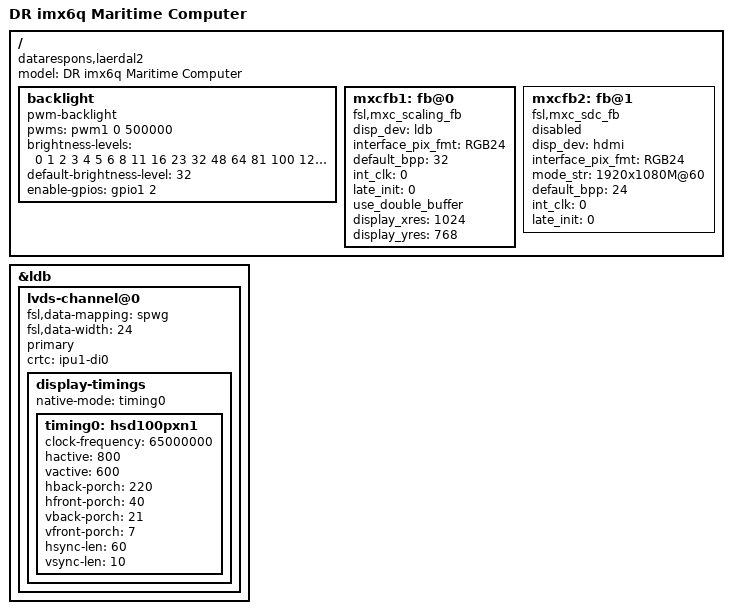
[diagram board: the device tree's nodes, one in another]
/*
 * Copyright 2015 DATA RESPONS AS
 * Copyright 2012 Freescale Semiconductor, Inc.
 * Copyright 2011 Linaro Ltd.
 *
 * The code contained herein is licensed under the GNU General Public
 * License. You may obtain a copy of the GNU General Public License
 * Version 2 or later at the following locations:
 *
 * http://www.opensource.org/licenses/gpl-license.html
 * http://www.gnu.org/copyleft/gpl.html
 */

/dts-v1/;

#include "imx6q.dtsi"
#include "mxxf1-common.dtsi"

/ {
    model = "DR imx6q Maritime Computer";
    compatible = "datarespons,laerdal2", "fsl,imx6q";

    backlight  {
        compatible = "pwm-backlight";
        pwms = <&pwm1 0 500000>;
        brightness-levels = < 0 1 2 3 4 5 6 8  11 16  23  32 48
                              64 81 100 121 144 169 196 225
                              256 289 324 361 400 441 484 529
                              576 625 676 729 784 841 900 961
                              1024 1089 1156 1225 1296 1369 1444 1521
                              1600 1681 1764 1849 1936 2025 2116 2209 >;
        default-brightness-level = <32>;
        enable-gpios = <&gpio1 2 GPIO_ACTIVE_HIGH>;
    };

    mxcfb1: fb@0 {
        compatible = "fsl,mxc_scaling_fb";
        disp_dev = "ldb";
        interface_pix_fmt = "RGB24";
        default_bpp = <32>;
        int_clk = <0>;
        late_init = <0>;
        use_double_buffer;
        display_xres = <1024>;
        display_yres = <768>;
        status = "okay";
    };

    mxcfb2: fb@1 {
        compatible = "fsl,mxc_sdc_fb";
        disp_dev = "hdmi";
        interface_pix_fmt = "RGB24";
        mode_str ="1920x1080M@60";
        default_bpp = <24>;
        int_clk = <0>;
        late_init = <0>;
        status = "disabled";
    };
};

&ldb {
    status = "okay";

    lvds-channel@0 {
        fsl,data-mapping = "spwg";
        fsl,data-width = <24>;
        status = "okay";
        primary;
        crtc = "ipu1-di0";

        display-timings {
            native-mode = <&timing0>;
            timing0: hsd100pxn1 {
                clock-frequency = <65000000>;
                hactive = <800>;
                vactive = <600>;
                hback-porch = <220>;
                hfront-porch = <40>;
                vback-porch = <21>;
                vfront-porch = <7>;
                hsync-len = <60>;
                vsync-len = <10>;
            };
        };
    };
};
